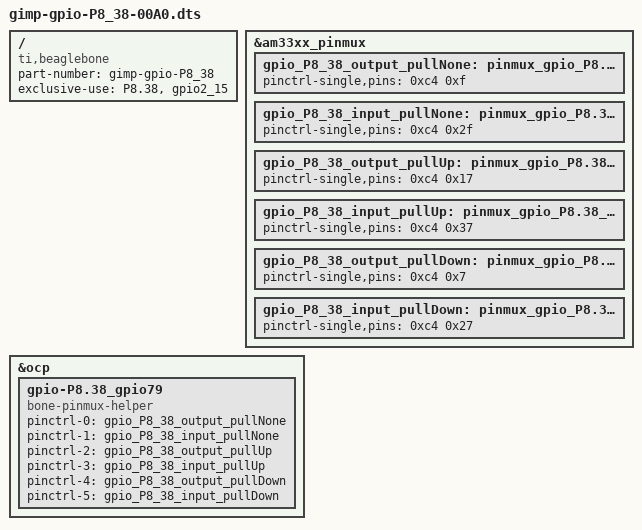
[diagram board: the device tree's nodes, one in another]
/*
* gimpbbio mux control of "P8.38" ("gpio2_15")
*/
/dts-v1/;
/plugin/;

/ {
	compatible = "ti,beaglebone", "ti,beaglebone-black";

	/* identification */
	part-number = "gimp-gpio-P8_38";
	/* version = "00A0"; */

	/* state the resources this cape uses */
	exclusive-use =
		/* the pin header uses */
		"P8.38",

		/* the hardware IP uses */
		"gpio2_15";
	
	
	/* output_pullNone state */
	fragment@0 {
		target = <&am33xx_pinmux>;
		__overlay__ {
			gpio_P8_38_output_pullNone: pinmux_gpio_P8.38_output_pullNone {
				pinctrl-single,pins = <
					0xc4 0xf
				>;
			};
		};
	};

	/* input_pullNone state */
	fragment@1 {
		target = <&am33xx_pinmux>;
		__overlay__ {
			gpio_P8_38_input_pullNone: pinmux_gpio_P8.38_input_pullNone {
				pinctrl-single,pins = <
					0xc4 0x2f
				>;
			};
		};
	};

	/* output_pullUp state */
	fragment@2 {
		target = <&am33xx_pinmux>;
		__overlay__ {
			gpio_P8_38_output_pullUp: pinmux_gpio_P8.38_output_pullUp {
				pinctrl-single,pins = <
					0xc4 0x17
				>;
			};
		};
	};

	/* input_pullUp state */
	fragment@3 {
		target = <&am33xx_pinmux>;
		__overlay__ {
			gpio_P8_38_input_pullUp: pinmux_gpio_P8.38_input_pullUp {
				pinctrl-single,pins = <
					0xc4 0x37
				>;
			};
		};
	};

	/* output_pullDown state */
	fragment@4 {
		target = <&am33xx_pinmux>;
		__overlay__ {
			gpio_P8_38_output_pullDown: pinmux_gpio_P8.38_output_pullDown {
				pinctrl-single,pins = <
					0xc4 0x7
				>;
			};
		};
	};

	/* input_pullDown state */
	fragment@5 {
		target = <&am33xx_pinmux>;
		__overlay__ {
			gpio_P8_38_input_pullDown: pinmux_gpio_P8.38_input_pullDown {
				pinctrl-single,pins = <
					0xc4 0x27
				>;
			};
		};
	};

	fragment@6 {
		target = <&ocp>;
		__overlay__ {
			gpio-P8.38_gpio79 {
				compatible = "bone-pinmux-helper";
				status = "okay";
				pinctrl-names = "output_pullNone", "input_pullNone", "output_pullUp", "input_pullUp", "output_pullDown", "input_pullDown";
				pinctrl-0 = <&gpio_P8_38_output_pullNone>;
				pinctrl-1 = <&gpio_P8_38_input_pullNone>;
				pinctrl-2 = <&gpio_P8_38_output_pullUp>;
				pinctrl-3 = <&gpio_P8_38_input_pullUp>;
				pinctrl-4 = <&gpio_P8_38_output_pullDown>;
				pinctrl-5 = <&gpio_P8_38_input_pullDown>;
			};
		};
	};

};
